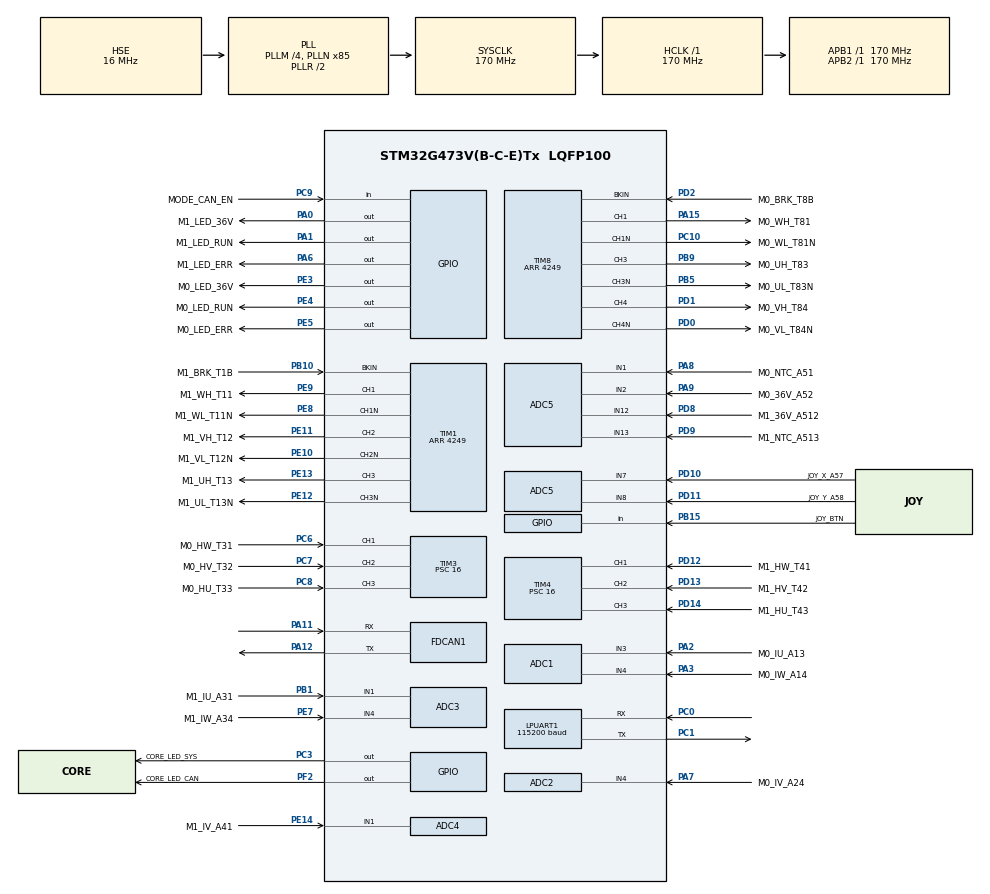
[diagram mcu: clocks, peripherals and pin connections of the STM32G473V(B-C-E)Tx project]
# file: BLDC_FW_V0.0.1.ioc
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ADC1.Channel-0\#ChannelRegularConversion=ADC_CHANNEL_3
ADC1.Channel-1\#ChannelRegularConversion=ADC_CHANNEL_4
ADC1.NbrOfConversion=2
ADC1.NbrOfConversionFlag=1
ADC1.OffsetNumber-1\#ChannelRegularConversion=ADC_OFFSET_NONE
ADC1.Rank-1\#ChannelRegularConversion=2
ADC1.SamplingTime-0\#ChannelRegularConversion=ADC_SAMPLETIME_47CYCLES_5
ADC1.SamplingTime-1\#ChannelRegularConversion=ADC_SAMPLETIME_47CYCLES_5
ADC1.master=1
ADC2.Channel-0\#ChannelRegularConversion=ADC_CHANNEL_4
ADC2.NbrOfConversionFlag=1
ADC2.OffsetNumber-0\#ChannelRegularConversion=ADC_OFFSET_NONE
ADC2.Rank-0\#ChannelRegularConversion=1
ADC2.SamplingTime-0\#ChannelRegularConversion=ADC_SAMPLETIME_47CYCLES_5
ADC3.Channel-0\#ChannelRegularConversion=ADC_CHANNEL_1
ADC3.Channel-1\#ChannelRegularConversion=ADC_CHANNEL_4
ADC3.NbrOfConversion=2
ADC3.NbrOfConversionFlag=1
ADC3.OffsetNumber-0\#ChannelRegularConversion=ADC_OFFSET_NONE
ADC3.OffsetNumber-1\#ChannelRegularConversion=ADC_OFFSET_NONE
ADC3.Rank-0\#ChannelRegularConversion=1
ADC3.Rank-1\#ChannelRegularConversion=2
ADC3.SamplingTime-0\#ChannelRegularConversion=ADC_SAMPLETIME_47CYCLES_5
ADC3.SamplingTime-1\#ChannelRegularConversion=ADC_SAMPLETIME_47CYCLES_5
ADC3.master=1
ADC4.Channel-0\#ChannelRegularConversion=ADC_CHANNEL_1
ADC4.NbrOfConversionFlag=1
ADC4.OffsetNumber-0\#ChannelRegularConversion=ADC_OFFSET_NONE
ADC4.Rank-0\#ChannelRegularConversion=1
ADC4.SamplingTime-0\#ChannelRegularConversion=ADC_SAMPLETIME_47CYCLES_5
ADC5.Channel-0\#ChannelRegularConversion=ADC_CHANNEL_1
ADC5.Channel-1\#ChannelRegularConversion=ADC_CHANNEL_2
ADC5.Channel-2\#ChannelRegularConversion=ADC_CHANNEL_12
ADC5.Channel-3\#ChannelRegularConversion=ADC_CHANNEL_13
ADC5.Channel-4\#ChannelRegularConversion=ADC_CHANNEL_7
ADC5.Channel-5\#ChannelRegularConversion=ADC_CHANNEL_8
ADC5.NbrOfConversion=6
ADC5.NbrOfConversionFlag=1
ADC5.OffsetNumber-0\#ChannelRegularConversion=ADC_OFFSET_NONE
ADC5.OffsetNumber-1\#ChannelRegularConversion=ADC_OFFSET_NONE
ADC5.OffsetNumber-2\#ChannelRegularConversion=ADC_OFFSET_NONE
ADC5.OffsetNumber-3\#ChannelRegularConversion=ADC_OFFSET_NONE
ADC5.OffsetNumber-4\#ChannelRegularConversion=ADC_OFFSET_NONE
ADC5.OffsetNumber-5\#ChannelRegularConversion=ADC_OFFSET_NONE
ADC5.Rank-0\#ChannelRegularConversion=1
ADC5.Rank-1\#ChannelRegularConversion=2
ADC5.Rank-2\#ChannelRegularConversion=3
ADC5.Rank-3\#ChannelRegularConversion=4
ADC5.Rank-4\#ChannelRegularConversion=5
ADC5.Rank-5\#ChannelRegularConversion=6
ADC5.SamplingTime-0\#ChannelRegularConversion=ADC_SAMPLETIME_92CYCLES_5
ADC5.SamplingTime-1\#ChannelRegularConversion=ADC_SAMPLETIME_92CYCLES_5
ADC5.SamplingTime-2\#ChannelRegularConversion=ADC_SAMPLETIME_92CYCLES_5
ADC5.SamplingTime-3\#ChannelRegularConversion=ADC_SAMPLETIME_92CYCLES_5
ADC5.SamplingTime-4\#ChannelRegularConversion=ADC_SAMPLETIME_92CYCLES_5
ADC5.SamplingTime-5\#ChannelRegularConversion=ADC_SAMPLETIME_92CYCLES_5
FDCAN1.AutoRetransmission=ENABLE
FDCAN1.CalculateBaudRateNominal=500000
FDCAN1.CalculateTimeBitNominal=2000
FDCAN1.CalculateTimeQuantumNominal=100.0
FDCAN1.NominalPrescaler=17
FDCAN1.NominalSyncJumpWidth=4
FDCAN1.NominalTimeSeg1=15
FDCAN1.NominalTimeSeg2=4
FDCAN1.StdFiltersNbr=1
LPUART1.BaudRate=115200
Mcu.Family=STM32G4
Mcu.Name=STM32G473V(B-C-E)Tx
Mcu.Package=LQFP100
NVIC.FDCAN1_IT0_IRQn=true\:3\:0\:true\:false\:true\:true\:true\:true
NVIC.PriorityGroup=NVIC_PRIORITYGROUP_4
NVIC.TIM1_BRK_TIM15_IRQn=true\:1\:0\:true\:false\:true\:true\:true\:true
NVIC.TIM1_UP_TIM16_IRQn=true\:1\:0\:true\:false\:true\:true\:true\:true
NVIC.TIM3_IRQn=true\:2\:0\:true\:false\:true\:true\:true\:true
NVIC.TIM4_IRQn=true\:2\:0\:true\:false\:true\:true\:true\:true
NVIC.TIM8_BRK_IRQn=true\:1\:0\:true\:false\:true\:true\:true\:true
NVIC.TIM8_UP_IRQn=true\:1\:0\:true\:false\:true\:true\:true\:true
PA0.GPIO_Label=M1_LED_36V
PA0.Signal=GPIO_Output
PA1.GPIO_Label=M1_LED_RUN
PA1.Signal=GPIO_Output
PA11.Mode=FDCAN_Activate
PA11.Signal=FDCAN1_RX
PA12.Mode=FDCAN_Activate
PA12.Signal=FDCAN1_TX
PA13.Mode=Serial_Wire
PA13.Signal=SYS_JTMS-SWDIO
PA14.Mode=Serial_Wire
PA14.Signal=SYS_JTCK-SWCLK
PA15.GPIO_Label=M0_WH_T81
PA15.Signal=S_TIM8_CH1
PA2.GPIO_Label=M0_IU_A13
PA2.Mode=IN3-Single-Ended
PA2.Signal=ADC1_IN3
PA3.GPIO_Label=M0_IW_A14
PA3.Mode=IN4-Single-Ended
PA3.Signal=ADC1_IN4
PA6.GPIO_Label=M1_LED_ERR
PA6.Signal=GPIO_Output
PA7.GPIO_Label=M0_IV_A24
PA7.Mode=IN4-Single-Ended
PA7.Signal=ADC2_IN4
PA8.GPIO_Label=M0_NTC_A51
PA8.Mode=IN1-Single-Ended
PA8.Signal=ADC5_IN1
PA9.GPIO_Label=M0_36V_A52
PA9.Mode=IN2-Single-Ended
PA9.Signal=ADC5_IN2
PB1.GPIO_Label=M1_IU_A31
PB1.Mode=IN1-Single-Ended
PB1.Signal=ADC3_IN1
PB10.GPIO_Label=M1_BRK_T1B
PB10.Mode=Activate-Break-Input
PB10.Signal=TIM1_BKIN
PB15.GPIO_Label=JOY_BTN
PB15.Signal=GPIO_Input
PB5.GPIO_Label=M0_UL_T83N
PB5.Mode=PWM Generation3 CH3 CH3N
PB5.Signal=TIM8_CH3N
PB9.GPIO_Label=M0_UH_T83
PB9.Signal=S_TIM8_CH3
PC0.Mode=Asynchronous
PC0.Signal=LPUART1_RX
PC1.Mode=Asynchronous
PC1.Signal=LPUART1_TX
PC10.GPIO_Label=M0_WL_T81N
PC10.Mode=PWM Generation1 CH1 CH1N
PC10.Signal=TIM8_CH1N
PC3.GPIO_Label=CORE_LED_SYS
PC3.Signal=GPIO_Output
PC6.GPIO_Label=M0_HW_T31
PC6.Signal=S_TIM3_CH1
PC7.GPIO_Label=M0_HV_T32
PC7.Signal=S_TIM3_CH2
PC8.GPIO_Label=M0_HU_T33
PC8.Signal=S_TIM3_CH3
PC9.GPIO_Label=MODE_CAN_EN
PC9.Signal=GPIO_Input
PD0.GPIO_Label=M0_VL_T84N
PD0.Mode=PWM Generation4 CH4 CH4N
PD0.Signal=TIM8_CH4N
PD1.GPIO_Label=M0_VH_T84
PD1.Signal=S_TIM8_CH4
PD10.GPIO_Label=JOY_X_A57
PD10.Mode=IN7-Single-Ended
PD10.Signal=ADC5_IN7
PD11.GPIO_Label=JOY_Y_A58
PD11.Mode=IN8-Single-Ended
PD11.Signal=ADC5_IN8
PD12.GPIO_Label=M1_HW_T41
PD12.Signal=S_TIM4_CH1
PD13.GPIO_Label=M1_HV_T42
PD13.Signal=S_TIM4_CH2
PD14.GPIO_Label=M1_HU_T43
PD14.Signal=S_TIM4_CH3
PD2.GPIO_Label=M0_BRK_T8B
PD2.Mode=Activate-Break-Input
PD2.Signal=TIM8_BKIN
PD8.GPIO_Label=M1_36V_A512
PD8.Mode=IN12-Single-Ended
PD8.Signal=ADC5_IN12
PD9.GPIO_Label=M1_NTC_A513
PD9.Mode=IN13-Single-Ended
PD9.Signal=ADC5_IN13
PE10.GPIO_Label=M1_VL_T12N
PE10.Mode=PWM Generation2 CH2 CH2N
PE10.Signal=TIM1_CH2N
PE11.GPIO_Label=M1_VH_T12
PE11.Signal=S_TIM1_CH2
PE12.GPIO_Label=M1_UL_T13N
PE12.Mode=PWM Generation3 CH3 CH3N
PE12.Signal=TIM1_CH3N
PE13.GPIO_Label=M1_UH_T13
PE13.Signal=S_TIM1_CH3
PE14.GPIO_Label=M1_IV_A41
PE14.Mode=IN1-Single-Ended
PE14.Signal=ADC4_IN1
PE3.GPIO_Label=M0_LED_36V
PE3.Signal=GPIO_Output
PE4.GPIO_Label=M0_LED_RUN
PE4.Signal=GPIO_Output
PE5.GPIO_Label=M0_LED_ERR
PE5.Signal=GPIO_Output
PE7.GPIO_Label=M1_IW_A34
PE7.Mode=IN4-Single-Ended
PE7.Signal=ADC3_IN4
PE8.GPIO_Label=M1_WL_T11N
PE8.Mode=PWM Generation1 CH1 CH1N
PE8.Signal=TIM1_CH1N
PE9.GPIO_Label=M1_WH_T11
PE9.Signal=S_TIM1_CH1
PF0-OSC_IN.Mode=HSE-External-Oscillator
PF0-OSC_IN.Signal=RCC_OSC_IN
PF1-OSC_OUT.Mode=HSE-External-Oscillator
PF1-OSC_OUT.Signal=RCC_OSC_OUT
PF2.GPIO_Label=CORE_LED_CAN
PF2.Signal=GPIO_Output
ProjectManager.HeapSize=0x200
ProjectManager.StackSize=0x400
ProjectManager.TargetToolchain=STM32CubeIDE
RCC.ADC12Freq_Value=170000000
RCC.ADC345Freq_Value=170000000
RCC.AHBFreq_Value=170000000
RCC.APB1Freq_Value=170000000
RCC.APB1TimFreq_Value=170000000
RCC.APB2Freq_Value=170000000
RCC.APB2TimFreq_Value=170000000
RCC.CortexFreq_Value=170000000
RCC.EXTERNAL_CLOCK_VALUE=12288000
RCC.HCLKFreq_Value=170000000
RCC.HSE_VALUE=16000000
RCC.HSI48_VALUE=48000000
RCC.HSI_VALUE=16000000
RCC.LSE_VALUE=32768
RCC.PLLM=RCC_PLLM_DIV4
RCC.PLLN=85
RCC.PLLSourceVirtual=RCC_PLLSOURCE_HSE
RCC.SYSCLKFreq_VALUE=170000000
RCC.SYSCLKSource=RCC_SYSCLKSOURCE_PLLCLK
RCC.USBFreq_Value=170000000
RCC.VCOOutputFreq_Value=340000000
SH.S_TIM1_CH1.0=TIM1_CH1,PWM Generation1 CH1 CH1N
SH.S_TIM1_CH2.0=TIM1_CH2,PWM Generation2 CH2 CH2N
SH.S_TIM1_CH3.0=TIM1_CH3,PWM Generation3 CH3 CH3N
SH.S_TIM3_CH1.0=TIM3_CH1,Xored_Inputs_Hall_Sensor_Interface
SH.S_TIM3_CH2.0=TIM3_CH2,Xored_Inputs_Hall_Sensor_Interface
SH.S_TIM3_CH3.0=TIM3_CH3,Xored_Inputs_Hall_Sensor_Interface
SH.S_TIM4_CH1.0=TIM4_CH1,Xored_Inputs_Hall_Sensor_Interface
SH.S_TIM4_CH2.0=TIM4_CH2,Xored_Inputs_Hall_Sensor_Interface
SH.S_TIM4_CH3.0=TIM4_CH3,Xored_Inputs_Hall_Sensor_Interface
SH.S_TIM8_CH1.0=TIM8_CH1,PWM Generation1 CH1 CH1N
SH.S_TIM8_CH3.0=TIM8_CH3,PWM Generation3 CH3 CH3N
SH.S_TIM8_CH4.0=TIM8_CH4,PWM Generation4 CH4 CH4N
TIM1.AutoReloadPreload=TIM_AUTORELOAD_PRELOAD_ENABLE
TIM1.AutomaticOutput=TIM_AUTOMATICOUTPUT_ENABLE
TIM1.BreakPolarity=TIM_BREAKPOLARITY_HIGH
TIM1.Channel-PWM\ Generation1\ CH1\ CH1N=TIM_CHANNEL_1
TIM1.Channel-PWM\ Generation2\ CH2\ CH2N=TIM_CHANNEL_2
TIM1.Channel-PWM\ Generation3\ CH3\ CH3N=TIM_CHANNEL_3
TIM1.CounterMode=TIM_COUNTERMODE_CENTERALIGNED1
TIM1.DeadTime=149
TIM1.DeadTimePreload=ENABLE
TIM1.PeriodNoDither=4249
TIM3.IC1Filter=8
TIM3.Prescaler=16
TIM4.IC1Filter=8
TIM4.Prescaler=16
TIM8.AutoReloadPreload=TIM_AUTORELOAD_PRELOAD_ENABLE
TIM8.AutomaticOutput=TIM_AUTOMATICOUTPUT_ENABLE
TIM8.BreakPolarity=TIM_BREAKPOLARITY_HIGH
TIM8.Channel-PWM\ Generation1\ CH1\ CH1N=TIM_CHANNEL_1
TIM8.Channel-PWM\ Generation3\ CH3\ CH3N=TIM_CHANNEL_3
TIM8.Channel-PWM\ Generation4\ CH4\ CH4N=TIM_CHANNEL_4
TIM8.CounterMode=TIM_COUNTERMODE_CENTERALIGNED1
TIM8.DeadTime=149
TIM8.DeadTimePreload=ENABLE
TIM8.PeriodNoDither=4249
VP_SYS_VS_DBSignals.Mode=DisableDeadBatterySignals
VP_TIM1_VS_ClockSourceINT.Mode=Internal
VP_TIM3_VS_ClockSourceINT.Mode=Internal
VP_TIM4_VS_ClockSourceINT.Mode=Internal
VP_TIM8_VS_ClockSourceINT.Mode=Internal
board=custom

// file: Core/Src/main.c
/* USER CODE BEGIN Header */
/**
  ******************************************************************************
  * @file           : main.c
  * @brief          : Main program body
  ******************************************************************************
  * @attention
  *
  * Copyright (c) 2026 STMicroelectronics.
  * All rights reserved.
  *
  * This software is licensed under terms that can be found in the LICENSE file
  * in the root directory of this software component.
  * If no LICENSE file comes with this software, it is provided AS-IS.
  *
  ******************************************************************************
  */
/* USER CODE END Header */
#include "main.h"

/* USER CODE BEGIN Includes */
#include "bldc_mgr.h"

/* USER CODE END Includes */

ADC_HandleTypeDef hadc1;
ADC_HandleTypeDef hadc2;
ADC_HandleTypeDef hadc3;
ADC_HandleTypeDef hadc4;
ADC_HandleTypeDef hadc5;

FDCAN_HandleTypeDef hfdcan1;

UART_HandleTypeDef hlpuart1;

TIM_HandleTypeDef htim1;
TIM_HandleTypeDef htim3;
TIM_HandleTypeDef htim4;
TIM_HandleTypeDef htim8;

void SystemClock_Config(void);
static void MX_GPIO_Init(void);
static void MX_TIM1_Init(void);
static void MX_TIM8_Init(void);
static void MX_ADC1_Init(void);
static void MX_ADC2_Init(void);
static void MX_ADC3_Init(void);
static void MX_ADC4_Init(void);
static void MX_ADC5_Init(void);
static void MX_FDCAN1_Init(void);
static void MX_LPUART1_UART_Init(void);
static void MX_TIM3_Init(void);
static void MX_TIM4_Init(void);

int main(void)
{

  /* MCU Configuration--------------------------------------------------------*/

  /* Reset of all peripherals, Initializes the Flash interface and the Systick. */
	HAL_Init();

  /* Configure the system clock */
  SystemClock_Config();

  /* Initialize all configured peripherals */
  MX_GPIO_Init();
  MX_TIM1_Init();
  MX_TIM8_Init();
  MX_ADC1_Init();
  MX_ADC2_Init();
  MX_ADC3_Init();
  MX_ADC4_Init();
  MX_ADC5_Init();
  MX_FDCAN1_Init();
  MX_LPUART1_UART_Init();
  MX_TIM3_Init();
  MX_TIM4_Init();
  /* USER CODE BEGIN 2 */
  BLDC_Init();
  /* USER CODE END 2 */

  /* Infinite loop */
  /* USER CODE BEGIN WHILE */
  while (1)
  {
	  BLDC_Run();

    /* USER CODE END WHILE */

  }
}

void SystemClock_Config(void)
{
  RCC_OscInitTypeDef RCC_OscInitStruct = {0};
  RCC_ClkInitTypeDef RCC_ClkInitStruct = {0};

  /** Configure the main internal regulator output voltage
  */
  HAL_PWREx_ControlVoltageScaling(PWR_REGULATOR_VOLTAGE_SCALE1_BOOST);

  /** Initializes the RCC Oscillators according to the specified parameters
  * in the RCC_OscInitTypeDef structure.
  */
  RCC_OscInitStruct.OscillatorType = RCC_OSCILLATORTYPE_HSE;
  RCC_OscInitStruct.HSEState = RCC_HSE_ON;
  RCC_OscInitStruct.PLL.PLLState = RCC_PLL_ON;
  RCC_OscInitStruct.PLL.PLLSource = RCC_PLLSOURCE_HSE;
  RCC_OscInitStruct.PLL.PLLM = RCC_PLLM_DIV4;
  RCC_OscInitStruct.PLL.PLLN = 85;
  RCC_OscInitStruct.PLL.PLLP = RCC_PLLP_DIV2;
  RCC_OscInitStruct.PLL.PLLQ = RCC_PLLQ_DIV2;
  RCC_OscInitStruct.PLL.PLLR = RCC_PLLR_DIV2;
  if (HAL_RCC_OscConfig(&RCC_OscInitStruct) != HAL_OK)
  {
    Error_Handler();
  }

  /** Initializes the CPU, AHB and APB buses clocks
  */
  RCC_ClkInitStruct.ClockType = RCC_CLOCKTYPE_HCLK|RCC_CLOCKTYPE_SYSCLK
                              |RCC_CLOCKTYPE_PCLK1|RCC_CLOCKTYPE_PCLK2;
  RCC_ClkInitStruct.SYSCLKSource = RCC_SYSCLKSOURCE_PLLCLK;
  RCC_ClkInitStruct.AHBCLKDivider = RCC_SYSCLK_DIV1;
  RCC_ClkInitStruct.APB1CLKDivider = RCC_HCLK_DIV1;
  RCC_ClkInitStruct.APB2CLKDivider = RCC_HCLK_DIV1;

  if (HAL_RCC_ClockConfig(&RCC_ClkInitStruct, FLASH_LATENCY_4) != HAL_OK)
  {
    Error_Handler();
  }
}

static void MX_ADC1_Init(void)
{

  ADC_MultiModeTypeDef multimode = {0};
  ADC_ChannelConfTypeDef sConfig = {0};

  /** Common config
  */
  hadc1.Instance = ADC1;
  hadc1.Init.ClockPrescaler = ADC_CLOCK_SYNC_PCLK_DIV4;
  hadc1.Init.Resolution = ADC_RESOLUTION_12B;
  hadc1.Init.DataAlign = ADC_DATAALIGN_RIGHT;
  hadc1.Init.GainCompensation = 0;
  hadc1.Init.ScanConvMode = ADC_SCAN_ENABLE;
  hadc1.Init.EOCSelection = ADC_EOC_SINGLE_CONV;
  hadc1.Init.LowPowerAutoWait = DISABLE;
  hadc1.Init.ContinuousConvMode = DISABLE;
  hadc1.Init.NbrOfConversion = 2;
  hadc1.Init.DiscontinuousConvMode = DISABLE;
  hadc1.Init.ExternalTrigConv = ADC_SOFTWARE_START;
  hadc1.Init.ExternalTrigConvEdge = ADC_EXTERNALTRIGCONVEDGE_NONE;
  hadc1.Init.DMAContinuousRequests = DISABLE;
  hadc1.Init.Overrun = ADC_OVR_DATA_PRESERVED;
  hadc1.Init.OversamplingMode = DISABLE;
  if (HAL_ADC_Init(&hadc1) != HAL_OK)
  {
    Error_Handler();
  }

  /** Configure the ADC multi-mode
  */
  multimode.Mode = ADC_MODE_INDEPENDENT;
  if (HAL_ADCEx_MultiModeConfigChannel(&hadc1, &multimode) != HAL_OK)
  {
    Error_Handler();
  }

  /** Configure Regular Channel
  */
  sConfig.Channel = ADC_CHANNEL_3;
  sConfig.Rank = ADC_REGULAR_RANK_1;
  sConfig.SamplingTime = ADC_SAMPLETIME_47CYCLES_5;
  sConfig.SingleDiff = ADC_SINGLE_ENDED;
  sConfig.OffsetNumber = ADC_OFFSET_NONE;
  sConfig.Offset = 0;
  if (HAL_ADC_ConfigChannel(&hadc1, &sConfig) != HAL_OK)
  {
    Error_Handler();
  }

  /** Configure Regular Channel
  */
  sConfig.Channel = ADC_CHANNEL_4;
  sConfig.Rank = ADC_REGULAR_RANK_2;
  if (HAL_ADC_ConfigChannel(&hadc1, &sConfig) != HAL_OK)
  {
    Error_Handler();
  }

}

static void MX_ADC2_Init(void)
{

  ADC_ChannelConfTypeDef sConfig = {0};

  /** Common config
  */
  hadc2.Instance = ADC2;
  hadc2.Init.ClockPrescaler = ADC_CLOCK_SYNC_PCLK_DIV4;
  hadc2.Init.Resolution = ADC_RESOLUTION_12B;
  hadc2.Init.DataAlign = ADC_DATAALIGN_RIGHT;
  hadc2.Init.GainCompensation = 0;
  hadc2.Init.ScanConvMode = ADC_SCAN_DISABLE;
  hadc2.Init.EOCSelection = ADC_EOC_SINGLE_CONV;
  hadc2.Init.LowPowerAutoWait = DISABLE;
  hadc2.Init.ContinuousConvMode = DISABLE;
  hadc2.Init.NbrOfConversion = 1;
  hadc2.Init.DiscontinuousConvMode = DISABLE;
  hadc2.Init.ExternalTrigConv = ADC_SOFTWARE_START;
  hadc2.Init.ExternalTrigConvEdge = ADC_EXTERNALTRIGCONVEDGE_NONE;
  hadc2.Init.DMAContinuousRequests = DISABLE;
  hadc2.Init.Overrun = ADC_OVR_DATA_PRESERVED;
  hadc2.Init.OversamplingMode = DISABLE;
  if (HAL_ADC_Init(&hadc2) != HAL_OK)
  {
    Error_Handler();
  }

  /** Configure Regular Channel
  */
  sConfig.Channel = ADC_CHANNEL_4;
  sConfig.Rank = ADC_REGULAR_RANK_1;
  sConfig.SamplingTime = ADC_SAMPLETIME_47CYCLES_5;
  sConfig.SingleDiff = ADC_SINGLE_ENDED;
  sConfig.OffsetNumber = ADC_OFFSET_NONE;
  sConfig.Offset = 0;
  if (HAL_ADC_ConfigChannel(&hadc2, &sConfig) != HAL_OK)
  {
    Error_Handler();
  }

}

static void MX_ADC3_Init(void)
{

  ADC_MultiModeTypeDef multimode = {0};
  ADC_ChannelConfTypeDef sConfig = {0};

  /** Common config
  */
  hadc3.Instance = ADC3;
  hadc3.Init.ClockPrescaler = ADC_CLOCK_SYNC_PCLK_DIV4;
  hadc3.Init.Resolution = ADC_RESOLUTION_12B;
  hadc3.Init.DataAlign = ADC_DATAALIGN_RIGHT;
  hadc3.Init.GainCompensation = 0;
  hadc3.Init.ScanConvMode = ADC_SCAN_ENABLE;
  hadc3.Init.EOCSelection = ADC_EOC_SINGLE_CONV;
  hadc3.Init.LowPowerAutoWait = DISABLE;
  hadc3.Init.ContinuousConvMode = DISABLE;
  hadc3.Init.NbrOfConversion = 2;
  hadc3.Init.DiscontinuousConvMode = DISABLE;
  hadc3.Init.ExternalTrigConv = ADC_SOFTWARE_START;
  hadc3.Init.ExternalTrigConvEdge = ADC_EXTERNALTRIGCONVEDGE_NONE;
  hadc3.Init.DMAContinuousRequests = DISABLE;
  hadc3.Init.Overrun = ADC_OVR_DATA_PRESERVED;
  hadc3.Init.OversamplingMode = DISABLE;
  if (HAL_ADC_Init(&hadc3) != HAL_OK)
  {
    Error_Handler();
  }

  /** Configure the ADC multi-mode
  */
  multimode.Mode = ADC_MODE_INDEPENDENT;
  if (HAL_ADCEx_MultiModeConfigChannel(&hadc3, &multimode) != HAL_OK)
  {
    Error_Handler();
  }

  /** Configure Regular Channel
  */
  sConfig.Channel = ADC_CHANNEL_1;
  sConfig.Rank = ADC_REGULAR_RANK_1;
  sConfig.SamplingTime = ADC_SAMPLETIME_47CYCLES_5;
  sConfig.SingleDiff = ADC_SINGLE_ENDED;
  sConfig.OffsetNumber = ADC_OFFSET_NONE;
  sConfig.Offset = 0;
  if (HAL_ADC_ConfigChannel(&hadc3, &sConfig) != HAL_OK)
  {
    Error_Handler();
  }

  /** Configure Regular Channel
  */
  sConfig.Channel = ADC_CHANNEL_4;
  sConfig.Rank = ADC_REGULAR_RANK_2;
  if (HAL_ADC_ConfigChannel(&hadc3, &sConfig) != HAL_OK)
  {
    Error_Handler();
  }

}

static void MX_ADC4_Init(void)
{

  ADC_ChannelConfTypeDef sConfig = {0};

  /** Common config
  */
  hadc4.Instance = ADC4;
  hadc4.Init.ClockPrescaler = ADC_CLOCK_SYNC_PCLK_DIV4;
  hadc4.Init.Resolution = ADC_RESOLUTION_12B;
  hadc4.Init.DataAlign = ADC_DATAALIGN_RIGHT;
  hadc4.Init.GainCompensation = 0;
  hadc4.Init.ScanConvMode = ADC_SCAN_DISABLE;
  hadc4.Init.EOCSelection = ADC_EOC_SINGLE_CONV;
  hadc4.Init.LowPowerAutoWait = DISABLE;
  hadc4.Init.ContinuousConvMode = DISABLE;
  hadc4.Init.NbrOfConversion = 1;
  hadc4.Init.DiscontinuousConvMode = DISABLE;
  hadc4.Init.ExternalTrigConv = ADC_SOFTWARE_START;
  hadc4.Init.ExternalTrigConvEdge = ADC_EXTERNALTRIGCONVEDGE_NONE;
  hadc4.Init.DMAContinuousRequests = DISABLE;
  hadc4.Init.Overrun = ADC_OVR_DATA_PRESERVED;
  hadc4.Init.OversamplingMode = DISABLE;
  if (HAL_ADC_Init(&hadc4) != HAL_OK)
  {
    Error_Handler();
  }

  /** Configure Regular Channel
  */
  sConfig.Channel = ADC_CHANNEL_1;
  sConfig.Rank = ADC_REGULAR_RANK_1;
  sConfig.SamplingTime = ADC_SAMPLETIME_47CYCLES_5;
  sConfig.SingleDiff = ADC_SINGLE_ENDED;
  sConfig.OffsetNumber = ADC_OFFSET_NONE;
  sConfig.Offset = 0;
  if (HAL_ADC_ConfigChannel(&hadc4, &sConfig) != HAL_OK)
  {
    Error_Handler();
  }

}

static void MX_ADC5_Init(void)
{

  ADC_ChannelConfTypeDef sConfig = {0};

  /** Common config
  */
  hadc5.Instance = ADC5;
  hadc5.Init.ClockPrescaler = ADC_CLOCK_SYNC_PCLK_DIV4;
  hadc5.Init.Resolution = ADC_RESOLUTION_12B;
  hadc5.Init.DataAlign = ADC_DATAALIGN_RIGHT;
  hadc5.Init.GainCompensation = 0;
  hadc5.Init.ScanConvMode = ADC_SCAN_ENABLE;
  hadc5.Init.EOCSelection = ADC_EOC_SINGLE_CONV;
  hadc5.Init.LowPowerAutoWait = DISABLE;
  hadc5.Init.ContinuousConvMode = DISABLE;
  hadc5.Init.NbrOfConversion = 6;
  hadc5.Init.DiscontinuousConvMode = DISABLE;
  hadc5.Init.ExternalTrigConv = ADC_SOFTWARE_START;
  hadc5.Init.ExternalTrigConvEdge = ADC_EXTERNALTRIGCONVEDGE_NONE;
  hadc5.Init.DMAContinuousRequests = DISABLE;
  hadc5.Init.Overrun = ADC_OVR_DATA_PRESERVED;
  hadc5.Init.OversamplingMode = DISABLE;
  if (HAL_ADC_Init(&hadc5) != HAL_OK)
  {
    Error_Handler();
  }

  /** Configure Regular Channel
  */
  sConfig.Channel = ADC_CHANNEL_1;
  sConfig.Rank = ADC_REGULAR_RANK_1;
  sConfig.SamplingTime = ADC_SAMPLETIME_92CYCLES_5;
  sConfig.SingleDiff = ADC_SINGLE_ENDED;
  sConfig.OffsetNumber = ADC_OFFSET_NONE;
  sConfig.Offset = 0;
  if (HAL_ADC_ConfigChannel(&hadc5, &sConfig) != HAL_OK)
  {
    Error_Handler();
  }

  /** Configure Regular Channel
  */
  sConfig.Channel = ADC_CHANNEL_2;
  sConfig.Rank = ADC_REGULAR_RANK_2;
  if (HAL_ADC_ConfigChannel(&hadc5, &sConfig) != HAL_OK)
  {
    Error_Handler();
  }

  /** Configure Regular Channel
  */
  sConfig.Channel = ADC_CHANNEL_12;
  sConfig.Rank = ADC_REGULAR_RANK_3;
  if (HAL_ADC_ConfigChannel(&hadc5, &sConfig) != HAL_OK)
  {
    Error_Handler();
  }

  /** Configure Regular Channel
  */
  sConfig.Channel = ADC_CHANNEL_13;
  sConfig.Rank = ADC_REGULAR_RANK_4;
  if (HAL_ADC_ConfigChannel(&hadc5, &sConfig) != HAL_OK)
  {
    Error_Handler();
  }

  /** Configure Regular Channel
  */
  sConfig.Channel = ADC_CHANNEL_7;
  sConfig.Rank = ADC_REGULAR_RANK_5;
  if (HAL_ADC_ConfigChannel(&hadc5, &sConfig) != HAL_OK)
  {
    Error_Handler();
  }

  /** Configure Regular Channel
  */
  sConfig.Channel = ADC_CHANNEL_8;
  sConfig.Rank = ADC_REGULAR_RANK_6;
  if (HAL_ADC_ConfigChannel(&hadc5, &sConfig) != HAL_OK)
  {
    Error_Handler();
  }

}

static void MX_FDCAN1_Init(void)
{

  hfdcan1.Instance = FDCAN1;
  hfdcan1.Init.ClockDivider = FDCAN_CLOCK_DIV1;
  hfdcan1.Init.FrameFormat = FDCAN_FRAME_CLASSIC;
  hfdcan1.Init.Mode = FDCAN_MODE_NORMAL;
  hfdcan1.Init.AutoRetransmission = ENABLE;
  hfdcan1.Init.TransmitPause = DISABLE;
  hfdcan1.Init.ProtocolException = DISABLE;
  hfdcan1.Init.NominalPrescaler = 17;
  hfdcan1.Init.NominalSyncJumpWidth = 4;
  hfdcan1.Init.NominalTimeSeg1 = 15;
  hfdcan1.Init.NominalTimeSeg2 = 4;
  hfdcan1.Init.DataPrescaler = 1;
  hfdcan1.Init.DataSyncJumpWidth = 1;
  hfdcan1.Init.DataTimeSeg1 = 1;
  hfdcan1.Init.DataTimeSeg2 = 1;
  hfdcan1.Init.StdFiltersNbr = 1;
  hfdcan1.Init.ExtFiltersNbr = 0;
  hfdcan1.Init.TxFifoQueueMode = FDCAN_TX_FIFO_OPERATION;
  if (HAL_FDCAN_Init(&hfdcan1) != HAL_OK)
  {
    Error_Handler();
  }

}

static void MX_LPUART1_UART_Init(void)
{

  hlpuart1.Instance = LPUART1;
  hlpuart1.Init.BaudRate = 115200;
  hlpuart1.Init.WordLength = UART_WORDLENGTH_8B;
  hlpuart1.Init.StopBits = UART_STOPBITS_1;
  hlpuart1.Init.Parity = UART_PARITY_NONE;
  hlpuart1.Init.Mode = UART_MODE_TX_RX;
  hlpuart1.Init.HwFlowCtl = UART_HWCONTROL_NONE;
  hlpuart1.Init.OneBitSampling = UART_ONE_BIT_SAMPLE_DISABLE;
  hlpuart1.Init.ClockPrescaler = UART_PRESCALER_DIV1;
  hlpuart1.AdvancedInit.AdvFeatureInit = UART_ADVFEATURE_NO_INIT;
  if (HAL_UART_Init(&hlpuart1) != HAL_OK)
  {
    Error_Handler();
  }
  if (HAL_UARTEx_SetTxFifoThreshold(&hlpuart1, UART_TXFIFO_THRESHOLD_1_8) != HAL_OK)
  {
    Error_Handler();
  }
  if (HAL_UARTEx_SetRxFifoThreshold(&hlpuart1, UART_RXFIFO_THRESHOLD_1_8) != HAL_OK)
  {
    Error_Handler();
  }
  if (HAL_UARTEx_DisableFifoMode(&hlpuart1) != HAL_OK)
  {
    Error_Handler();
  }

}

static void MX_TIM1_Init(void)
{

  TIM_ClockConfigTypeDef sClockSourceConfig = {0};
  TIM_MasterConfigTypeDef sMasterConfig = {0};
  TIMEx_BreakInputConfigTypeDef sBreakInputConfig = {0};
  TIM_OC_InitTypeDef sConfigOC = {0};
  TIM_BreakDeadTimeConfigTypeDef sBreakDeadTimeConfig = {0};

  htim1.Instance = TIM1;
  htim1.Init.Prescaler = 0;
  htim1.Init.CounterMode = TIM_COUNTERMODE_CENTERALIGNED1;
  htim1.Init.Period = 4249;
  htim1.Init.ClockDivision = TIM_CLOCKDIVISION_DIV1;
  htim1.Init.RepetitionCounter = 0;
  htim1.Init.AutoReloadPreload = TIM_AUTORELOAD_PRELOAD_ENABLE;
  if (HAL_TIM_Base_Init(&htim1) != HAL_OK)
  {
    Error_Handler();
  }
  sClockSourceConfig.ClockSource = TIM_CLOCKSOURCE_INTERNAL;
  if (HAL_TIM_ConfigClockSource(&htim1, &sClockSourceConfig) != HAL_OK)
  {
    Error_Handler();
  }
  if (HAL_TIM_PWM_Init(&htim1) != HAL_OK)
  {
    Error_Handler();
  }
  sMasterConfig.MasterOutputTrigger = TIM_TRGO_RESET;
  sMasterConfig.MasterOutputTrigger2 = TIM_TRGO2_RESET;
  sMasterConfig.MasterSlaveMode = TIM_MASTERSLAVEMODE_DISABLE;
  if (HAL_TIMEx_MasterConfigSynchronization(&htim1, &sMasterConfig) != HAL_OK)
  {
    Error_Handler();
  }
  sBreakInputConfig.Source = TIM_BREAKINPUTSOURCE_BKIN;
  sBreakInputConfig.Enable = TIM_BREAKINPUTSOURCE_ENABLE;
  sBreakInputConfig.Polarity = TIM_BREAKINPUTSOURCE_POLARITY_HIGH;
  if (HAL_TIMEx_ConfigBreakInput(&htim1, TIM_BREAKINPUT_BRK, &sBreakInputConfig) != HAL_OK)
  {
    Error_Handler();
  }
  sConfigOC.OCMode = TIM_OCMODE_PWM1;
  sConfigOC.Pulse = 0;
  sConfigOC.OCPolarity = TIM_OCPOLARITY_HIGH;
  sConfigOC.OCNPolarity = TIM_OCNPOLARITY_HIGH;
  sConfigOC.OCFastMode = TIM_OCFAST_DISABLE;
  sConfigOC.OCIdleState = TIM_OCIDLESTATE_RESET;
  sConfigOC.OCNIdleState = TIM_OCNIDLESTATE_RESET;
  if (HAL_TIM_PWM_ConfigChannel(&htim1, &sConfigOC, TIM_CHANNEL_1) != HAL_OK)
  {
    Error_Handler();
  }
  if (HAL_TIM_PWM_ConfigChannel(&htim1, &sConfigOC, TIM_CHANNEL_2) != HAL_OK)
  {
    Error_Handler();
  }
  if (HAL_TIM_PWM_ConfigChannel(&htim1, &sConfigOC, TIM_CHANNEL_3) != HAL_OK)
  {
    Error_Handler();
  }
  HAL_TIMEx_EnableDeadTimePreload(&htim1);
  sBreakDeadTimeConfig.OffStateRunMode = TIM_OSSR_DISABLE;
  sBreakDeadTimeConfig.OffStateIDLEMode = TIM_OSSI_DISABLE;
  sBreakDeadTimeConfig.LockLevel = TIM_LOCKLEVEL_OFF;
  sBreakDeadTimeConfig.DeadTime = 149;
  sBreakDeadTimeConfig.BreakState = TIM_BREAK_ENABLE;
  sBreakDeadTimeConfig.BreakPolarity = TIM_BREAKPOLARITY_HIGH;
  sBreakDeadTimeConfig.BreakFilter = 0;
  sBreakDeadTimeConfig.BreakAFMode = TIM_BREAK_AFMODE_INPUT;
  sBreakDeadTimeConfig.Break2State = TIM_BREAK2_DISABLE;
  sBreakDeadTimeConfig.Break2Polarity = TIM_BREAK2POLARITY_HIGH;
  sBreakDeadTimeConfig.Break2Filter = 0;
  sBreakDeadTimeConfig.Break2AFMode = TIM_BREAK_AFMODE_INPUT;
  sBreakDeadTimeConfig.AutomaticOutput = TIM_AUTOMATICOUTPUT_ENABLE;
  if (HAL_TIMEx_ConfigBreakDeadTime(&htim1, &sBreakDeadTimeConfig) != HAL_OK)
  {
    Error_Handler();
  }
  HAL_TIM_MspPostInit(&htim1);

}

static void MX_TIM3_Init(void)
{

  TIM_ClockConfigTypeDef sClockSourceConfig = {0};
  TIM_HallSensor_InitTypeDef sConfig = {0};
  TIM_MasterConfigTypeDef sMasterConfig = {0};

  htim3.Instance = TIM3;
  htim3.Init.Prescaler = 16;
  htim3.Init.CounterMode = TIM_COUNTERMODE_UP;
  htim3.Init.Period = 65535;
  htim3.Init.ClockDivision = TIM_CLOCKDIVISION_DIV1;
  htim3.Init.AutoReloadPreload = TIM_AUTORELOAD_PRELOAD_DISABLE;
  if (HAL_TIM_Base_Init(&htim3) != HAL_OK)
  {
    Error_Handler();
  }
  sClockSourceConfig.ClockSource = TIM_CLOCKSOURCE_INTERNAL;
  if (HAL_TIM_ConfigClockSource(&htim3, &sClockSourceConfig) != HAL_OK)
  {
    Error_Handler();
  }
  sConfig.IC1Polarity = TIM_ICPOLARITY_RISING;
  sConfig.IC1Prescaler = TIM_ICPSC_DIV1;
  sConfig.IC1Filter = 8;
  sConfig.Commutation_Delay = 0;
  if (HAL_TIMEx_HallSensor_Init(&htim3, &sConfig) != HAL_OK)
  {
    Error_Handler();
  }
  sMasterConfig.MasterOutputTrigger = TIM_TRGO_OC2REF;
  sMasterConfig.MasterSlaveMode = TIM_MASTERSLAVEMODE_DISABLE;
  if (HAL_TIMEx_MasterConfigSynchronization(&htim3, &sMasterConfig) != HAL_OK)
  {
    Error_Handler();
  }

}

static void MX_TIM4_Init(void)
{

  TIM_ClockConfigTypeDef sClockSourceConfig = {0};
  TIM_HallSensor_InitTypeDef sConfig = {0};
  TIM_MasterConfigTypeDef sMasterConfig = {0};

  htim4.Instance = TIM4;
  htim4.Init.Prescaler = 16;
  htim4.Init.CounterMode = TIM_COUNTERMODE_UP;
  htim4.Init.Period = 65535;
  htim4.Init.ClockDivision = TIM_CLOCKDIVISION_DIV1;
  htim4.Init.AutoReloadPreload = TIM_AUTORELOAD_PRELOAD_DISABLE;
  if (HAL_TIM_Base_Init(&htim4) != HAL_OK)
  {
    Error_Handler();
  }
  sClockSourceConfig.ClockSource = TIM_CLOCKSOURCE_INTERNAL;
  if (HAL_TIM_ConfigClockSource(&htim4, &sClockSourceConfig) != HAL_OK)
  {
    Error_Handler();
  }
  sConfig.IC1Polarity = TIM_ICPOLARITY_RISING;
  sConfig.IC1Prescaler = TIM_ICPSC_DIV1;
  sConfig.IC1Filter = 8;
  sConfig.Commutation_Delay = 0;
  if (HAL_TIMEx_HallSensor_Init(&htim4, &sConfig) != HAL_OK)
  {
    Error_Handler();
  }
  sMasterConfig.MasterOutputTrigger = TIM_TRGO_OC2REF;
  sMasterConfig.MasterSlaveMode = TIM_MASTERSLAVEMODE_DISABLE;
  if (HAL_TIMEx_MasterConfigSynchronization(&htim4, &sMasterConfig) != HAL_OK)
  {
    Error_Handler();
  }

}

static void MX_TIM8_Init(void)
{

  TIM_ClockConfigTypeDef sClockSourceConfig = {0};
  TIM_MasterConfigTypeDef sMasterConfig = {0};
  TIMEx_BreakInputConfigTypeDef sBreakInputConfig = {0};
  TIM_OC_InitTypeDef sConfigOC = {0};
  TIM_BreakDeadTimeConfigTypeDef sBreakDeadTimeConfig = {0};

  htim8.Instance = TIM8;
  htim8.Init.Prescaler = 0;
  htim8.Init.CounterMode = TIM_COUNTERMODE_CENTERALIGNED1;
  htim8.Init.Period = 4249;
  htim8.Init.ClockDivision = TIM_CLOCKDIVISION_DIV1;
  htim8.Init.RepetitionCounter = 0;
  htim8.Init.AutoReloadPreload = TIM_AUTORELOAD_PRELOAD_ENABLE;
  if (HAL_TIM_Base_Init(&htim8) != HAL_OK)
  {
    Error_Handler();
  }
  sClockSourceConfig.ClockSource = TIM_CLOCKSOURCE_INTERNAL;
  if (HAL_TIM_ConfigClockSource(&htim8, &sClockSourceConfig) != HAL_OK)
  {
    Error_Handler();
  }
  if (HAL_TIM_PWM_Init(&htim8) != HAL_OK)
  {
    Error_Handler();
  }
  sMasterConfig.MasterOutputTrigger = TIM_TRGO_RESET;
  sMasterConfig.MasterOutputTrigger2 = TIM_TRGO2_RESET;
  sMasterConfig.MasterSlaveMode = TIM_MASTERSLAVEMODE_DISABLE;
  if (HAL_TIMEx_MasterConfigSynchronization(&htim8, &sMasterConfig) != HAL_OK)
  {
    Error_Handler();
  }
  sBreakInputConfig.Source = TIM_BREAKINPUTSOURCE_BKIN;
  sBreakInputConfig.Enable = TIM_BREAKINPUTSOURCE_ENABLE;
  sBreakInputConfig.Polarity = TIM_BREAKINPUTSOURCE_POLARITY_HIGH;
  if (HAL_TIMEx_ConfigBreakInput(&htim8, TIM_BREAKINPUT_BRK, &sBreakInputConfig) != HAL_OK)
  {
    Error_Handler();
  }
  sConfigOC.OCMode = TIM_OCMODE_PWM1;
  sConfigOC.Pulse = 0;
  sConfigOC.OCPolarity = TIM_OCPOLARITY_HIGH;
  sConfigOC.OCNPolarity = TIM_OCNPOLARITY_HIGH;
  sConfigOC.OCFastMode = TIM_OCFAST_DISABLE;
  sConfigOC.OCIdleState = TIM_OCIDLESTATE_RESET;
  sConfigOC.OCNIdleState = TIM_OCNIDLESTATE_RESET;
  if (HAL_TIM_PWM_ConfigChannel(&htim8, &sConfigOC, TIM_CHANNEL_1) != HAL_OK)
  {
    Error_Handler();
  }
  if (HAL_TIM_PWM_ConfigChannel(&htim8, &sConfigOC, TIM_CHANNEL_3) != HAL_OK)
  {
    Error_Handler();
  }
  if (HAL_TIM_PWM_ConfigChannel(&htim8, &sConfigOC, TIM_CHANNEL_4) != HAL_OK)
  {
    Error_Handler();
  }
  HAL_TIMEx_EnableDeadTimePreload(&htim8);
  sBreakDeadTimeConfig.OffStateRunMode = TIM_OSSR_DISABLE;
  sBreakDeadTimeConfig.OffStateIDLEMode = TIM_OSSI_DISABLE;
  sBreakDeadTimeConfig.LockLevel = TIM_LOCKLEVEL_OFF;
  sBreakDeadTimeConfig.DeadTime = 149;
  sBreakDeadTimeConfig.BreakState = TIM_BREAK_ENABLE;
  sBreakDeadTimeConfig.BreakPolarity = TIM_BREAKPOLARITY_HIGH;
  sBreakDeadTimeConfig.BreakFilter = 0;
  sBreakDeadTimeConfig.BreakAFMode = TIM_BREAK_AFMODE_INPUT;
  sBreakDeadTimeConfig.Break2State = TIM_BREAK2_DISABLE;
  sBreakDeadTimeConfig.Break2Polarity = TIM_BREAK2POLARITY_HIGH;
  sBreakDeadTimeConfig.Break2Filter = 0;
  sBreakDeadTimeConfig.Break2AFMode = TIM_BREAK_AFMODE_INPUT;
  sBreakDeadTimeConfig.AutomaticOutput = TIM_AUTOMATICOUTPUT_ENABLE;
  if (HAL_TIMEx_ConfigBreakDeadTime(&htim8, &sBreakDeadTimeConfig) != HAL_OK)
  {
    Error_Handler();
  }
  HAL_TIM_MspPostInit(&htim8);

}

static void MX_GPIO_Init(void)
{
  GPIO_InitTypeDef GPIO_InitStruct = {0};

  /* GPIO Ports Clock Enable */
  __HAL_RCC_GPIOE_CLK_ENABLE();
  __HAL_RCC_GPIOF_CLK_ENABLE();
  __HAL_RCC_GPIOC_CLK_ENABLE();
  __HAL_RCC_GPIOA_CLK_ENABLE();
  __HAL_RCC_GPIOB_CLK_ENABLE();
  __HAL_RCC_GPIOD_CLK_ENABLE();

  /*Configure GPIO pin Output Level */
  HAL_GPIO_WritePin(GPIOE, M0_LED_36V_Pin|M0_LED_RUN_Pin|M0_LED_ERR_Pin, GPIO_PIN_RESET);

  /*Configure GPIO pin Output Level */
  HAL_GPIO_WritePin(CORE_LED_SYS_GPIO_Port, CORE_LED_SYS_Pin, GPIO_PIN_RESET);

  /*Configure GPIO pin Output Level */
  HAL_GPIO_WritePin(CORE_LED_CAN_GPIO_Port, CORE_LED_CAN_Pin, GPIO_PIN_RESET);

  /*Configure GPIO pin Output Level */
  HAL_GPIO_WritePin(GPIOA, M1_LED_36V_Pin|M1_LED_RUN_Pin|M1_LED_ERR_Pin, GPIO_PIN_RESET);

  /*Configure GPIO pins : M0_LED_36V_Pin M0_LED_RUN_Pin M0_LED_ERR_Pin */
  GPIO_InitStruct.Pin = M0_LED_36V_Pin|M0_LED_RUN_Pin|M0_LED_ERR_Pin;
  GPIO_InitStruct.Mode = GPIO_MODE_OUTPUT_PP;
  GPIO_InitStruct.Pull = GPIO_NOPULL;
  GPIO_InitStruct.Speed = GPIO_SPEED_FREQ_LOW;
  HAL_GPIO_Init(GPIOE, &GPIO_InitStruct);

  /*Configure GPIO pin : CORE_LED_SYS_Pin */
  GPIO_InitStruct.Pin = CORE_LED_SYS_Pin;
  GPIO_InitStruct.Mode = GPIO_MODE_OUTPUT_PP;
  GPIO_InitStruct.Pull = GPIO_NOPULL;
  GPIO_InitStruct.Speed = GPIO_SPEED_FREQ_LOW;
  HAL_GPIO_Init(CORE_LED_SYS_GPIO_Port, &GPIO_InitStruct);

  /*Configure GPIO pin : CORE_LED_CAN_Pin */
  GPIO_InitStruct.Pin = CORE_LED_CAN_Pin;
  GPIO_InitStruct.Mode = GPIO_MODE_OUTPUT_PP;
  GPIO_InitStruct.Pull = GPIO_NOPULL;
  GPIO_InitStruct.Speed = GPIO_SPEED_FREQ_LOW;
  HAL_GPIO_Init(CORE_LED_CAN_GPIO_Port, &GPIO_InitStruct);

  /*Configure GPIO pins : M1_LED_36V_Pin M1_LED_RUN_Pin M1_LED_ERR_Pin */
  GPIO_InitStruct.Pin = M1_LED_36V_Pin|M1_LED_RUN_Pin|M1_LED_ERR_Pin;
  GPIO_InitStruct.Mode = GPIO_MODE_OUTPUT_PP;
  GPIO_InitStruct.Pull = GPIO_NOPULL;
  GPIO_InitStruct.Speed = GPIO_SPEED_FREQ_LOW;
  HAL_GPIO_Init(GPIOA, &GPIO_InitStruct);

  /*Configure GPIO pin : JOY_BTN_Pin */
  GPIO_InitStruct.Pin = JOY_BTN_Pin;
  GPIO_InitStruct.Mode = GPIO_MODE_INPUT;
  GPIO_InitStruct.Pull = GPIO_NOPULL;
  HAL_GPIO_Init(JOY_BTN_GPIO_Port, &GPIO_InitStruct);

  /*Configure GPIO pin : MODE_CAN_EN_Pin */
  GPIO_InitStruct.Pin = MODE_CAN_EN_Pin;
  GPIO_InitStruct.Mode = GPIO_MODE_INPUT;
  GPIO_InitStruct.Pull = GPIO_NOPULL;
  HAL_GPIO_Init(MODE_CAN_EN_GPIO_Port, &GPIO_InitStruct);

}

void Error_Handler(void)
{
  __disable_irq();
  while (1)
  {
  }
}
